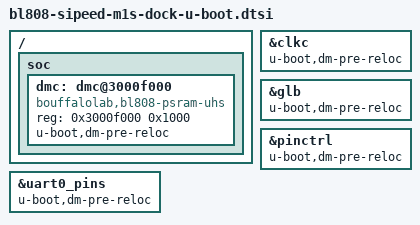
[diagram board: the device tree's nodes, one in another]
// SPDX-License-Identifier: (GPL-2.0 OR MIT)
/*
 * Copyright (C) Michael Walle <michael@walle.cc>
 */

/ {
	soc {
		dmc: dmc@3000f000 {
			compatible = "bouffalolab,bl808-psram-uhs";
			reg = <0x3000f000 0x1000>;
			u-boot,dm-pre-reloc;
		};
	};
};

&clkc {
	u-boot,dm-pre-reloc;
};

&glb {
	u-boot,dm-pre-reloc;
};

&pinctrl {
	u-boot,dm-pre-reloc;
};

&uart0_pins {
	u-boot,dm-pre-reloc;
};
